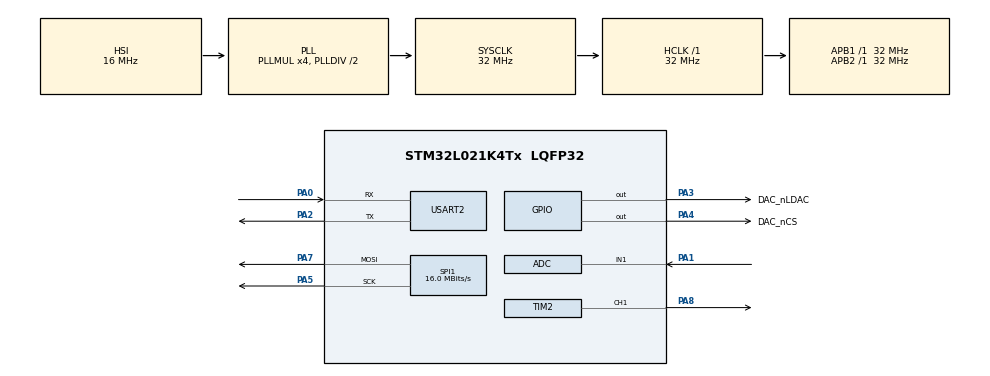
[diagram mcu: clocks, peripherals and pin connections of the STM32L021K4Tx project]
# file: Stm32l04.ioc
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Mcu.Family=STM32L0
Mcu.Name=STM32L021K4Tx
Mcu.Package=LQFP32
NVIC.TIM21_IRQn=true\:0\:0\:false\:false\:true\:true\:true\:true
PA0-CK_IN.Mode=Asynchronous
PA0-CK_IN.Signal=USART2_RX
PA1.Mode=IN1
PA1.Signal=ADC_IN1
PA13.Mode=Serial_Wire
PA13.Signal=SYS_SWDIO
PA14.Mode=Serial_Wire
PA14.Signal=SYS_SWCLK
PA2.Mode=Asynchronous
PA2.Signal=USART2_TX
PA3.GPIO_Label=DAC_nLDAC
PA3.Signal=GPIO_Output
PA4.GPIO_Label=DAC_nCS
PA4.Signal=GPIO_Output
PA5.Mode=TX_Only_Simplex_Unidirect_Master
PA5.Signal=SPI1_SCK
PA7.Mode=TX_Only_Simplex_Unidirect_Master
PA7.Signal=SPI1_MOSI
PA8.Signal=S_TIM2_CH1
ProjectManager.HeapSize=0x200
ProjectManager.StackSize=0x400
ProjectManager.TargetToolchain=Makefile
RCC.ADCFreq_Value=16000000
RCC.AHBFreq_Value=32000000
RCC.APB1Freq_Value=32000000
RCC.APB1TimFreq_Value=32000000
RCC.APB2Freq_Value=32000000
RCC.APB2TimFreq_Value=32000000
RCC.HCLKFreq_Value=32000000
RCC.HSE_VALUE=8000000
RCC.HSI16_VALUE=16000000
RCC.HSI_VALUE=16000000
RCC.LSE_VALUE=32768
RCC.MSIClockRange=RCC_MSIRANGE_6
RCC.MSI_VALUE=4194000
RCC.PLLMUL=RCC_PLLMUL_4
RCC.SYSCLKFreq_VALUE=32000000
RCC.SYSCLKSource=RCC_SYSCLKSOURCE_PLLCLK
RCC.VCOOutputFreq_Value=64000000
SH.S_TIM2_CH1.0=TIM2_CH1,PWM Generation1 CH1
SPI1.CRCCalculation=SPI_CRCCALCULATION_DISABLE
SPI1.CalculateBaudRate=16.0 MBits/s
SPI1.Direction=SPI_DIRECTION_2LINES
SPI1.Mode=SPI_MODE_MASTER
SPI1.VirtualType=VM_MASTER
TIM2.Channel-PWM\ Generation1\ CH1=TIM_CHANNEL_1
TIM2.Period=255
TIM2.Prescaler=125-1
TIM21.Period=255
TIM21.Prescaler=125-1
USART2.VirtualMode-Asynchronous=VM_ASYNC
VP_TIM21_VS_ClockSourceINT.Mode=Internal
VP_TIM2_VS_ClockSourceINT.Mode=Internal
board=custom

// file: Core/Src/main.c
/* USER CODE BEGIN Header */
/**
  ******************************************************************************
  * @file           : main.c
  * @brief          : Main program body
  ******************************************************************************
  * @attention
  *
  * Copyright (c) 2023 STMicroelectronics.
  * All rights reserved.
  *
  * This software is licensed under terms that can be found in the LICENSE file
  * in the root directory of this software component.
  * If no LICENSE file comes with this software, it is provided AS-IS.
  *
  ******************************************************************************
  */
/* USER CODE END Header */
#include "main.h"
#include "adc.h"
#include "spi.h"
#include "tim.h"
#include "usart.h"
#include "gpio.h"
#include "Serial.h"

void SystemClock_Config(void);

int main(void)
{

  /* MCU Configuration--------------------------------------------------------*/

  /* Reset of all peripherals, Initializes the Flash interface and the Systick. */
  HAL_Init();

  /* Configure the system clock */
  SystemClock_Config();

  /* Initialize all configured peripherals */
  MX_GPIO_Init();
  MX_USART2_UART_Init();
  MX_ADC_Init();
  MX_SPI1_Init();
  MX_TIM2_Init();
  MX_TIM21_Init();
  /* USER CODE BEGIN 2 */
  //LedStart();
  //TimeBaseStartIT();
  /* USER CODE END 2 */

  /* Infinite loop */
  /* USER CODE BEGIN WHILE */
  while (1)
  {
    //HAL_GPIO_WritePin( GPIOA, GPIO_PIN_8, GPIO_PIN_SET );
    //HAL_Delay(1000);
    //HAL_GPIO_WritePin( GPIOA, GPIO_PIN_8, GPIO_PIN_RESET );
    //HAL_Delay(1000);

    //LedPulse();
    //HAL_Delay(100);

    char ch;
    SerialReceiveChar(&ch,1);
    SerialTransmit(&ch, 1);

    /* USER CODE END WHILE */

  }
}

void SystemClock_Config(void)
{
  RCC_OscInitTypeDef RCC_OscInitStruct = {0};
  RCC_ClkInitTypeDef RCC_ClkInitStruct = {0};
  RCC_PeriphCLKInitTypeDef PeriphClkInit = {0};

  /** Configure the main internal regulator output voltage
  */
  __HAL_PWR_VOLTAGESCALING_CONFIG(PWR_REGULATOR_VOLTAGE_SCALE1);

  /** Initializes the RCC Oscillators according to the specified parameters
  * in the RCC_OscInitTypeDef structure.
  */
  RCC_OscInitStruct.OscillatorType = RCC_OSCILLATORTYPE_HSI;
  RCC_OscInitStruct.HSIState = RCC_HSI_ON;
  RCC_OscInitStruct.HSICalibrationValue = RCC_HSICALIBRATION_DEFAULT;
  RCC_OscInitStruct.PLL.PLLState = RCC_PLL_ON;
  RCC_OscInitStruct.PLL.PLLSource = RCC_PLLSOURCE_HSI;
  RCC_OscInitStruct.PLL.PLLMUL = RCC_PLLMUL_4;
  RCC_OscInitStruct.PLL.PLLDIV = RCC_PLLDIV_2;
  if (HAL_RCC_OscConfig(&RCC_OscInitStruct) != HAL_OK)
  {
    Error_Handler();
  }

  /** Initializes the CPU, AHB and APB buses clocks
  */
  RCC_ClkInitStruct.ClockType = RCC_CLOCKTYPE_HCLK|RCC_CLOCKTYPE_SYSCLK
                              |RCC_CLOCKTYPE_PCLK1|RCC_CLOCKTYPE_PCLK2;
  RCC_ClkInitStruct.SYSCLKSource = RCC_SYSCLKSOURCE_PLLCLK;
  RCC_ClkInitStruct.AHBCLKDivider = RCC_SYSCLK_DIV1;
  RCC_ClkInitStruct.APB1CLKDivider = RCC_HCLK_DIV1;
  RCC_ClkInitStruct.APB2CLKDivider = RCC_HCLK_DIV1;

  if (HAL_RCC_ClockConfig(&RCC_ClkInitStruct, FLASH_LATENCY_1) != HAL_OK)
  {
    Error_Handler();
  }
  PeriphClkInit.PeriphClockSelection = RCC_PERIPHCLK_USART2;
  PeriphClkInit.Usart2ClockSelection = RCC_USART2CLKSOURCE_PCLK1;
  if (HAL_RCCEx_PeriphCLKConfig(&PeriphClkInit) != HAL_OK)
  {
    Error_Handler();
  }
}

void Error_Handler(void)
{
  __disable_irq();
  while (1)
  {
  }
}
